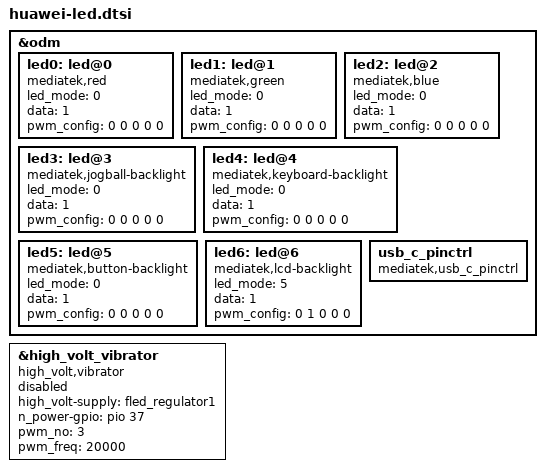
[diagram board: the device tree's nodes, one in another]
&odm {
	led0:led@0 {
		compatible = "mediatek,red";
		led_mode = <0>;
		data = <1>;
		pwm_config = <0 0 0 0 0>;
	};
	led1:led@1 {
		compatible = "mediatek,green";
		led_mode = <0>;
		data = <1>;
		pwm_config = <0 0 0 0 0>;
	};
	led2:led@2 {
		compatible = "mediatek,blue";
		led_mode = <0>;
		data = <1>;
		pwm_config = <0 0 0 0 0>;
	};
	led3:led@3 {
		compatible = "mediatek,jogball-backlight";
		led_mode = <0>;
		data = <1>;
		pwm_config = <0 0 0 0 0>;
	};
	led4:led@4 {
		compatible = "mediatek,keyboard-backlight";
		led_mode = <0>;
		data = <1>;
		pwm_config = <0 0 0 0 0>;
	};
	led5:led@5 {
		compatible = "mediatek,button-backlight";
		led_mode = <0>;
		data = <1>;
		pwm_config = <0 0 0 0 0>;
	};
	led6:led@6 {
		compatible = "mediatek,lcd-backlight";
		led_mode = <5>;
		data = <1>;
		pwm_config = <0 1 0 0 0>;
	};
	usb_c_pinctrl:usb_c_pinctrl {
		compatible = "mediatek,usb_c_pinctrl";
	};
};
&high_volt_vibrator {
	compatible = "high_volt,vibrator";
	high_volt-supply = <&fled_regulator1>;
	n_power-gpio = <&pio 37 0>;
	pwm_no = <3>;
	pwm_freq = <20000>;
	status = "disabled";
};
